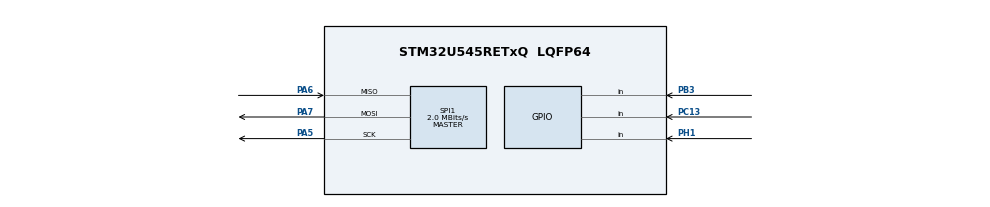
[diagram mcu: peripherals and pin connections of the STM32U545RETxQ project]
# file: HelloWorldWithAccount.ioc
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CORTEX_M33_NS.userName=CORTEX_M33
Mcu.Family=STM32U5
Mcu.Name=STM32U545RETxQ
Mcu.Package=LQFP64
NVIC.PriorityGroup=NVIC_PRIORITYGROUP_4
PA5.Mode=Full_Duplex_Master
PA5.Signal=SPI1_SCK
PA6.Mode=Full_Duplex_Master
PA6.Signal=SPI1_MISO
PA7.Mode=Full_Duplex_Master
PA7.Signal=SPI1_MOSI
PB3\ (JTDO/TRACESWO).Signal=GPIO_Input
PC13.Signal=GPIO_Input
PH1-OSC_OUT\ (PH1).Signal=GPIO_Input
PWR.PowerMode=PWR_SMPS_SUPPLY
PWR.SRAM2PowerDownInRunMode=__NULL
ProjectManager.HeapSize=0x200
ProjectManager.StackSize=0x400
ProjectManager.TargetToolchain=STM32CubeIDE
RCC.ADCFreq_Value=16000000
RCC.DACCLockSelectionVirtual=RCC_DAC1CLKSOURCE_LSI
RCC.DACCLockSelectionVirtualString=RCC_DAC1CLKSOURCE_LSI
RCC.EPOD_VALUE=4000000
RCC.HSE_VALUE=16000000
RCC.HSI48_VALUE=48000000
RCC.HSI_VALUE=16000000
RCC.LSE_VALUE=32768
RCC.LSIDIV_VALUE=32000
RCC.MSI_VALUE=4000000
RCC.USBFreq_Value=48000000
RCC.VCOOutputFreq_Value=516000000
SPI1.CalculateBaudRate=2.0 MBits/s
SPI1.Direction=SPI_DIRECTION_2LINES
SPI1.Mode=SPI_MODE_MASTER
SPI1.VirtualType=VM_MASTER
VP_AES_VS_AES.Mode=AES_Activate
VP_LPBAMQUEUE_VS_QUEUE.Mode=QUEUEMODE
VP_LPBAM_VS_SIG1.Mode=SmartRun
VP_LPBAM_VS_SIG4.Mode=LPDMA1
VP_LPDMA1_VS_LPDMACH0.Mode=LINKEDLIST_LPDMACH0
VP_MEMORYMAP_VS_MEMORYMAP.Mode=CurAppReg
VP_PWR_VS_LPOM.Mode=PowerOptimisation
VP_PWR_VS_SECSignals.Mode=Security/Privilege
VP_RTC_VS_RTC_Activate.Mode=RTC_Enabled
board=custom

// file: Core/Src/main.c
/* USER CODE BEGIN Header */
/**
  ******************************************************************************
  * @file           : main.c
  * @brief          : Main program body
  ******************************************************************************
  * @attention
  *
  * Copyright (c) 2024 STMicroelectronics.
  * All rights reserved.
  *
  * This software is licensed under terms that can be found in the LICENSE file
  * in the root directory of this software component.
  * If no LICENSE file comes with this software, it is provided AS-IS.
  *
  ******************************************************************************
  */
/* USER CODE END Header */
#include "main.h"

/* USER CODE BEGIN Includes */

#include "string.h"
#include "radioUtils.h"
#include "WindowSensorSystem.h"

/* USER CODE END Includes */

CRYP_HandleTypeDef hcryp;
__ALIGN_BEGIN static const uint32_t pKeyAES[4] __ALIGN_END = {
                            0x00000000,0x00000000,0x00000000,0x00000000};

DMA_HandleTypeDef handle_LPDMA1_Channel0;

RTC_HandleTypeDef hrtc;

SPI_HandleTypeDef hspi1;

void SystemClock_Config(void);
static void SystemPower_Config(void);
static void MX_GPIO_Init(void);
static void MX_LPDMA1_Init(void);
static void MX_RTC_Init(void);
static void MX_SPI1_Init(void);
static void MX_AES_Init(void);

int main(void)
{

  /* MCU Configuration--------------------------------------------------------*/

  /* Reset of all peripherals, Initializes the Flash interface and the Systick. */
  HAL_Init();

  /* Configure the System Power */
  SystemPower_Config();

  /* Configure the system clock */
  SystemClock_Config();

  /* Initialize all configured peripherals */
  MX_GPIO_Init();
  MX_LPDMA1_Init();
  MX_RTC_Init();
  MX_SPI1_Init();
  MX_AES_Init();
  /* USER CODE BEGIN 2 */

  startSystem();

  /* USER CODE END 2 */

  /* Infinite loop */

}

void SystemClock_Config(void)
{
  RCC_OscInitTypeDef RCC_OscInitStruct = {0};
  RCC_ClkInitTypeDef RCC_ClkInitStruct = {0};

  /** Configure the main internal regulator output voltage
  */
  if (HAL_PWREx_ControlVoltageScaling(PWR_REGULATOR_VOLTAGE_SCALE4) != HAL_OK)
  {
    Error_Handler();
  }

  /** Initializes the CPU, AHB and APB buses clocks
  */
  RCC_OscInitStruct.OscillatorType = RCC_OSCILLATORTYPE_LSI|RCC_OSCILLATORTYPE_MSI;
  RCC_OscInitStruct.LSIState = RCC_LSI_ON;
  RCC_OscInitStruct.MSIState = RCC_MSI_ON;
  RCC_OscInitStruct.MSICalibrationValue = RCC_MSICALIBRATION_DEFAULT;
  RCC_OscInitStruct.MSIClockRange = RCC_MSIRANGE_4;
  RCC_OscInitStruct.LSIDiv = RCC_LSI_DIV1;
  RCC_OscInitStruct.PLL.PLLState = RCC_PLL_NONE;
  if (HAL_RCC_OscConfig(&RCC_OscInitStruct) != HAL_OK)
  {
    Error_Handler();
  }

  /** Initializes the CPU, AHB and APB buses clocks
  */
  RCC_ClkInitStruct.ClockType = RCC_CLOCKTYPE_HCLK|RCC_CLOCKTYPE_SYSCLK
                              |RCC_CLOCKTYPE_PCLK1|RCC_CLOCKTYPE_PCLK2
                              |RCC_CLOCKTYPE_PCLK3;
  RCC_ClkInitStruct.SYSCLKSource = RCC_SYSCLKSOURCE_MSI;
  RCC_ClkInitStruct.AHBCLKDivider = RCC_SYSCLK_DIV1;
  RCC_ClkInitStruct.APB1CLKDivider = RCC_HCLK_DIV1;
  RCC_ClkInitStruct.APB2CLKDivider = RCC_HCLK_DIV1;
  RCC_ClkInitStruct.APB3CLKDivider = RCC_HCLK_DIV1;

  if (HAL_RCC_ClockConfig(&RCC_ClkInitStruct, FLASH_LATENCY_0) != HAL_OK)
  {
    Error_Handler();
  }
}

/**
  * @brief Power Configuration
  * @retval None
  */
static void SystemPower_Config(void)
{

  /*
   * Switch to SMPS regulator instead of LDO
   */
  if (HAL_PWREx_ConfigSupply(PWR_SMPS_SUPPLY) != HAL_OK)
  {
    Error_Handler();
  }
}

static void MX_AES_Init(void)
{

  hcryp.Instance = AES;
  hcryp.Init.DataType = CRYP_NO_SWAP;
  hcryp.Init.KeySize = CRYP_KEYSIZE_128B;
  hcryp.Init.pKey = (uint32_t *)pKeyAES;
  hcryp.Init.Algorithm = CRYP_AES_ECB;
  hcryp.Init.DataWidthUnit = CRYP_DATAWIDTHUNIT_WORD;
  hcryp.Init.HeaderWidthUnit = CRYP_HEADERWIDTHUNIT_WORD;
  hcryp.Init.KeyIVConfigSkip = CRYP_KEYIVCONFIG_ALWAYS;
  hcryp.Init.KeyMode = CRYP_KEYMODE_NORMAL;
  if (HAL_CRYP_Init(&hcryp) != HAL_OK)
  {
    Error_Handler();
  }

}

static void MX_LPDMA1_Init(void)
{

  /* Peripheral clock enable */
  __HAL_RCC_LPDMA1_CLK_ENABLE();

  handle_LPDMA1_Channel0.Instance = LPDMA1_Channel0;
  handle_LPDMA1_Channel0.InitLinkedList.Priority = DMA_LOW_PRIORITY_LOW_WEIGHT;
  handle_LPDMA1_Channel0.InitLinkedList.LinkStepMode = DMA_LSM_FULL_EXECUTION;
  handle_LPDMA1_Channel0.InitLinkedList.TransferEventMode = DMA_TCEM_LAST_LL_ITEM_TRANSFER;
  handle_LPDMA1_Channel0.InitLinkedList.LinkedListMode = DMA_LINKEDLIST_NORMAL;
  if (HAL_DMAEx_List_Init(&handle_LPDMA1_Channel0) != HAL_OK)
  {
    Error_Handler();
  }
  if (HAL_DMA_ConfigChannelAttributes(&handle_LPDMA1_Channel0, DMA_CHANNEL_NPRIV) != HAL_OK)
  {
    Error_Handler();
  }

}

static void MX_RTC_Init(void)
{

  RTC_PrivilegeStateTypeDef privilegeState = {0};

  /** Initialize RTC Only
  */
  hrtc.Instance = RTC;
  hrtc.Init.HourFormat = RTC_HOURFORMAT_24;
  hrtc.Init.AsynchPrediv = 127;
  hrtc.Init.SynchPrediv = 255;
  hrtc.Init.OutPut = RTC_OUTPUT_DISABLE;
  hrtc.Init.OutPutRemap = RTC_OUTPUT_REMAP_NONE;
  hrtc.Init.OutPutPolarity = RTC_OUTPUT_POLARITY_HIGH;
  hrtc.Init.OutPutType = RTC_OUTPUT_TYPE_OPENDRAIN;
  hrtc.Init.OutPutPullUp = RTC_OUTPUT_PULLUP_NONE;
  hrtc.Init.BinMode = RTC_BINARY_NONE;
  if (HAL_RTC_Init(&hrtc) != HAL_OK)
  {
    Error_Handler();
  }
  privilegeState.rtcPrivilegeFull = RTC_PRIVILEGE_FULL_NO;
  privilegeState.backupRegisterPrivZone = RTC_PRIVILEGE_BKUP_ZONE_NONE;
  privilegeState.backupRegisterStartZone2 = RTC_BKP_DR0;
  privilegeState.backupRegisterStartZone3 = RTC_BKP_DR0;
  if (HAL_RTCEx_PrivilegeModeSet(&hrtc, &privilegeState) != HAL_OK)
  {
    Error_Handler();
  }

}

static void MX_SPI1_Init(void)
{

  SPI_AutonomousModeConfTypeDef HAL_SPI_AutonomousMode_Cfg_Struct = {0};

  /* SPI1 parameter configuration*/
  hspi1.Instance = SPI1;
  hspi1.Init.Mode = SPI_MODE_MASTER;
  hspi1.Init.Direction = SPI_DIRECTION_2LINES;
  hspi1.Init.DataSize = SPI_DATASIZE_4BIT;
  hspi1.Init.CLKPolarity = SPI_POLARITY_LOW;
  hspi1.Init.CLKPhase = SPI_PHASE_1EDGE;
  hspi1.Init.NSS = SPI_NSS_SOFT;
  hspi1.Init.BaudRatePrescaler = SPI_BAUDRATEPRESCALER_2;
  hspi1.Init.FirstBit = SPI_FIRSTBIT_MSB;
  hspi1.Init.TIMode = SPI_TIMODE_DISABLE;
  hspi1.Init.CRCCalculation = SPI_CRCCALCULATION_DISABLE;
  hspi1.Init.CRCPolynomial = 0x7;
  hspi1.Init.NSSPMode = SPI_NSS_PULSE_ENABLE;
  hspi1.Init.NSSPolarity = SPI_NSS_POLARITY_LOW;
  hspi1.Init.FifoThreshold = SPI_FIFO_THRESHOLD_01DATA;
  hspi1.Init.MasterSSIdleness = SPI_MASTER_SS_IDLENESS_00CYCLE;
  hspi1.Init.MasterInterDataIdleness = SPI_MASTER_INTERDATA_IDLENESS_00CYCLE;
  hspi1.Init.MasterReceiverAutoSusp = SPI_MASTER_RX_AUTOSUSP_DISABLE;
  hspi1.Init.MasterKeepIOState = SPI_MASTER_KEEP_IO_STATE_DISABLE;
  hspi1.Init.IOSwap = SPI_IO_SWAP_DISABLE;
  hspi1.Init.ReadyMasterManagement = SPI_RDY_MASTER_MANAGEMENT_INTERNALLY;
  hspi1.Init.ReadyPolarity = SPI_RDY_POLARITY_HIGH;
  if (HAL_SPI_Init(&hspi1) != HAL_OK)
  {
    Error_Handler();
  }
  HAL_SPI_AutonomousMode_Cfg_Struct.TriggerState = SPI_AUTO_MODE_DISABLE;
  HAL_SPI_AutonomousMode_Cfg_Struct.TriggerSelection = SPI_GRP1_GPDMA_CH0_TCF_TRG;
  HAL_SPI_AutonomousMode_Cfg_Struct.TriggerPolarity = SPI_TRIG_POLARITY_RISING;
  if (HAL_SPIEx_SetConfigAutonomousMode(&hspi1, &HAL_SPI_AutonomousMode_Cfg_Struct) != HAL_OK)
  {
    Error_Handler();
  }

}

static void MX_GPIO_Init(void)
{
  GPIO_InitTypeDef GPIO_InitStruct = {0};

  /* GPIO Ports Clock Enable */
  __HAL_RCC_GPIOC_CLK_ENABLE();
  __HAL_RCC_GPIOH_CLK_ENABLE();
  __HAL_RCC_GPIOA_CLK_ENABLE();
  __HAL_RCC_GPIOB_CLK_ENABLE();

  /*Configure GPIO pin : PC13 */
  GPIO_InitStruct.Pin = GPIO_PIN_13;
  GPIO_InitStruct.Mode = GPIO_MODE_INPUT;
  GPIO_InitStruct.Pull = GPIO_NOPULL;
  HAL_GPIO_Init(GPIOC, &GPIO_InitStruct);

  /*Configure GPIO pin : PH1 */
  GPIO_InitStruct.Pin = GPIO_PIN_1;
  GPIO_InitStruct.Mode = GPIO_MODE_INPUT;
  GPIO_InitStruct.Pull = GPIO_NOPULL;
  HAL_GPIO_Init(GPIOH, &GPIO_InitStruct);

  /*Configure GPIO pin : PB3 */
  GPIO_InitStruct.Pin = GPIO_PIN_3;
  GPIO_InitStruct.Mode = GPIO_MODE_INPUT;
  GPIO_InitStruct.Pull = GPIO_NOPULL;
  HAL_GPIO_Init(GPIOB, &GPIO_InitStruct);

}

void Error_Handler(void)
{
  __disable_irq();
  while (1)
  {
  }
}
